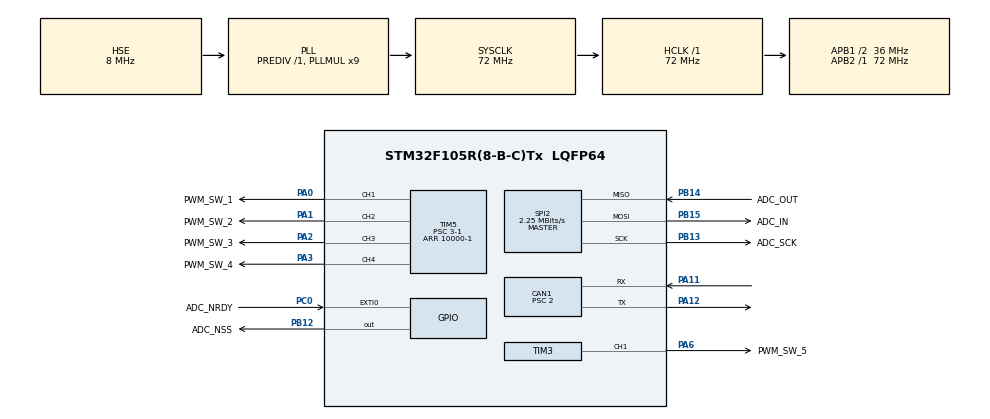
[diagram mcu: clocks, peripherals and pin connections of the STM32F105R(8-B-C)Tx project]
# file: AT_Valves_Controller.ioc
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CAN1.ABOM=ENABLE
CAN1.BS1=CAN_BS1_15TQ
CAN1.BS2=CAN_BS2_2TQ
CAN1.CalculateBaudRate=1000000
CAN1.CalculateTimeBit=1000
CAN1.CalculateTimeQuantum=55.55555555555556
CAN1.Prescaler=2
CAN1.TXFP=ENABLE
Dma.Request0=SPI2_TX
Dma.Request1=SPI2_RX
Dma.SPI2_RX.1.Direction=DMA_PERIPH_TO_MEMORY
Dma.SPI2_RX.1.Instance=DMA1_Channel4
Dma.SPI2_RX.1.MemDataAlignment=DMA_MDATAALIGN_BYTE
Dma.SPI2_RX.1.MemInc=DMA_MINC_ENABLE
Dma.SPI2_RX.1.Mode=DMA_NORMAL
Dma.SPI2_RX.1.PeriphDataAlignment=DMA_PDATAALIGN_BYTE
Dma.SPI2_RX.1.PeriphInc=DMA_PINC_DISABLE
Dma.SPI2_RX.1.Priority=DMA_PRIORITY_LOW
Dma.SPI2_TX.0.Direction=DMA_MEMORY_TO_PERIPH
Dma.SPI2_TX.0.Instance=DMA1_Channel5
Dma.SPI2_TX.0.MemDataAlignment=DMA_MDATAALIGN_BYTE
Dma.SPI2_TX.0.MemInc=DMA_MINC_ENABLE
Dma.SPI2_TX.0.Mode=DMA_NORMAL
Dma.SPI2_TX.0.PeriphDataAlignment=DMA_PDATAALIGN_BYTE
Dma.SPI2_TX.0.PeriphInc=DMA_PINC_DISABLE
Dma.SPI2_TX.0.Priority=DMA_PRIORITY_LOW
Mcu.Family=STM32F1
Mcu.Name=STM32F105R(8-B-C)Tx
Mcu.Package=LQFP64
NVIC.CAN1_RX0_IRQn=true\:0\:0\:false\:true\:true\:4\:true\:true
NVIC.CAN1_TX_IRQn=true\:0\:0\:false\:true\:true\:5\:true\:true
NVIC.DMA1_Channel4_IRQn=true\:1\:0\:true\:true\:true\:2\:true\:true
NVIC.DMA1_Channel5_IRQn=true\:1\:0\:true\:true\:true\:3\:true\:true
NVIC.EXTI0_IRQn=true\:1\:0\:true\:true\:true\:1\:true\:true
NVIC.PriorityGroup=NVIC_PRIORITYGROUP_4
NVIC.TIM6_IRQn=true\:2\:0\:true\:true\:true\:6\:true\:true
PA0-WKUP.GPIO_Label=PWM_SW_1
PA0-WKUP.GPIO_Speed=GPIO_SPEED_FREQ_HIGH
PA0-WKUP.Signal=S_TIM5_CH1
PA1.GPIO_Label=PWM_SW_2
PA1.GPIO_Speed=GPIO_SPEED_FREQ_HIGH
PA1.Signal=S_TIM5_CH2
PA11.Mode=CAN_Activate
PA11.Signal=CAN1_RX
PA12.GPIO_Speed=GPIO_SPEED_FREQ_HIGH
PA12.Mode=CAN_Activate
PA12.Signal=CAN1_TX
PA13.Mode=Serial_Wire
PA13.Signal=SYS_JTMS-SWDIO
PA14.Mode=Serial_Wire
PA14.Signal=SYS_JTCK-SWCLK
PA2.GPIO_Label=PWM_SW_3
PA2.GPIO_Speed=GPIO_SPEED_FREQ_HIGH
PA2.Signal=S_TIM5_CH3
PA3.GPIO_Label=PWM_SW_4
PA3.GPIO_Speed=GPIO_SPEED_FREQ_HIGH
PA3.Signal=S_TIM5_CH4
PA6.GPIO_Label=PWM_SW_5
PA6.GPIO_Speed=GPIO_SPEED_FREQ_HIGH
PA6.Signal=S_TIM3_CH1
PB12.GPIO_Label=ADC_NSS
PB12.GPIO_Speed=GPIO_SPEED_FREQ_HIGH
PB12.PinState=GPIO_PIN_SET
PB12.Signal=GPIO_Output
PB13.GPIO_Label=ADC_SCK
PB13.GPIO_Speed=GPIO_SPEED_FREQ_HIGH
PB13.Mode=Full_Duplex_Master
PB13.Signal=SPI2_SCK
PB14.GPIO_Label=ADC_OUT
PB14.Mode=Full_Duplex_Master
PB14.Signal=SPI2_MISO
PB15.GPIO_Label=ADC_IN
PB15.GPIO_Speed=GPIO_SPEED_FREQ_HIGH
PB15.Mode=Full_Duplex_Master
PB15.Signal=SPI2_MOSI
PC0.GPIO_Label=ADC_NRDY
PC0.GPIO_ModeDefaultEXTI=GPIO_MODE_IT_FALLING
PC0.Signal=GPXTI0
PD0-OSC_IN.Mode=HSE-External-Oscillator
PD0-OSC_IN.Signal=RCC_OSC_IN
PD1-OSC_OUT.Mode=HSE-External-Oscillator
PD1-OSC_OUT.Signal=RCC_OSC_OUT
ProjectManager.HeapSize=0x200
ProjectManager.StackSize=0x400
ProjectManager.TargetToolchain=STM32CubeIDE
RCC.AHBFreq_Value=72000000
RCC.APB1CLKDivider=RCC_HCLK_DIV2
RCC.APB1Freq_Value=36000000
RCC.APB1TimFreq_Value=72000000
RCC.APB2Freq_Value=72000000
RCC.APB2TimFreq_Value=72000000
RCC.HCLKFreq_Value=72000000
RCC.PLLMUL=RCC_PLL_MUL9
RCC.PLLSourceVirtual=RCC_PLLSOURCE_HSE
RCC.SYSCLKFreq_VALUE=72000000
RCC.SYSCLKSource=RCC_SYSCLKSOURCE_PLLCLK
RCC.USBFreq_Value=48000000
SH.S_TIM3_CH1.0=TIM3_CH1,PWM Generation1 CH1
SH.S_TIM5_CH1.0=TIM5_CH1,PWM Generation1 CH1
SH.S_TIM5_CH2.0=TIM5_CH2,PWM Generation2 CH2
SH.S_TIM5_CH3.0=TIM5_CH3,PWM Generation3 CH3
SH.S_TIM5_CH4.0=TIM5_CH4,PWM Generation4 CH4
SPI2.BaudRatePrescaler=SPI_BAUDRATEPRESCALER_16
SPI2.CLKPhase=SPI_PHASE_2EDGE
SPI2.CLKPolarity=SPI_POLARITY_HIGH
SPI2.CalculateBaudRate=2.25 MBits/s
SPI2.DataSize=SPI_DATASIZE_8BIT
SPI2.Direction=SPI_DIRECTION_2LINES
SPI2.FirstBit=SPI_FIRSTBIT_MSB
SPI2.Mode=SPI_MODE_MASTER
SPI2.VirtualType=VM_MASTER
TIM3.AutoReloadPreload=TIM_AUTORELOAD_PRELOAD_ENABLE
TIM3.Channel-PWM\ Generation1\ CH1=TIM_CHANNEL_1
TIM3.OCFastMode_PWM-PWM\ Generation1\ CH1=TIM_OCFAST_DISABLE
TIM3.OCMode_PWM-PWM\ Generation1\ CH1=TIM_OCMODE_PWM1
TIM3.OCPolarity_1=TIM_OCPOLARITY_HIGH
TIM3.Period=10000-1
TIM3.Prescaler=3-1
TIM5.AutoReloadPreload=TIM_AUTORELOAD_PRELOAD_ENABLE
TIM5.Channel-PWM\ Generation1\ CH1=TIM_CHANNEL_1
TIM5.Channel-PWM\ Generation2\ CH2=TIM_CHANNEL_2
TIM5.Channel-PWM\ Generation3\ CH3=TIM_CHANNEL_3
TIM5.Channel-PWM\ Generation4\ CH4=TIM_CHANNEL_4
TIM5.OCFastMode_PWM-PWM\ Generation1\ CH1=TIM_OCFAST_DISABLE
TIM5.OCFastMode_PWM-PWM\ Generation2\ CH2=TIM_OCFAST_DISABLE
TIM5.OCFastMode_PWM-PWM\ Generation3\ CH3=TIM_OCFAST_DISABLE
TIM5.OCFastMode_PWM-PWM\ Generation4\ CH4=TIM_OCFAST_DISABLE
TIM5.OCMode_PWM-PWM\ Generation1\ CH1=TIM_OCMODE_PWM1
TIM5.OCMode_PWM-PWM\ Generation2\ CH2=TIM_OCMODE_PWM1
TIM5.OCMode_PWM-PWM\ Generation3\ CH3=TIM_OCMODE_PWM1
TIM5.OCMode_PWM-PWM\ Generation4\ CH4=TIM_OCMODE_PWM1
TIM5.OCPolarity_1=TIM_OCPOLARITY_HIGH
TIM5.OCPolarity_2=TIM_OCPOLARITY_HIGH
TIM5.OCPolarity_3=TIM_OCPOLARITY_HIGH
TIM5.OCPolarity_4=TIM_OCPOLARITY_HIGH
TIM5.Period=10000-1
TIM5.Prescaler=3-1
TIM6.AutoReloadPreload=TIM_AUTORELOAD_PRELOAD_ENABLE
TIM6.Period=50-1
TIM6.Prescaler=7200-1
VP_TIM3_VS_ClockSourceINT.Mode=Internal
VP_TIM5_VS_ClockSourceINT.Mode=Internal
VP_TIM6_VS_ClockSourceINT.Mode=Enable_Timer
board=custom

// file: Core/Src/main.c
/* USER CODE BEGIN Header */
/**
  ******************************************************************************
  * @file           : main.c
  * @brief          : Main program body
  ******************************************************************************
  * @attention
  *
  * Copyright (c) 2023 STMicroelectronics.
  * All rights reserved.
  *
  * This software is licensed under terms that can be found in the LICENSE file
  * in the root directory of this software component.
  * If no LICENSE file comes with this software, it is provided AS-IS.
  *
  ******************************************************************************
  */
/* USER CODE END Header */
#include "main.h"
#include "can.h"
#include "dma.h"
#include "spi.h"
#include "tim.h"
#include "gpio.h"

/* USER CODE BEGIN Includes */
#include "user_logic.h"
/* USER CODE END Includes */

void SystemClock_Config(void);
static void MX_NVIC_Init(void);

int main(void)
{
  __disable_irq();

  /* MCU Configuration--------------------------------------------------------*/

  /* Reset of all peripherals, Initializes the Flash interface and the Systick. */
  HAL_Init();

  /* Configure the system clock */
  SystemClock_Config();

  /* Initialize all configured peripherals */
  MX_GPIO_Init();
  MX_DMA_Init();
  MX_CAN1_Init();
  MX_SPI2_Init();
  MX_TIM3_Init();
  MX_TIM5_Init();
  MX_TIM6_Init();

  /* Initialize interrupts */
  MX_NVIC_Init();
  /* USER CODE BEGIN 2 */
  User_Init();
  __enable_irq();
  /* USER CODE END 2 */

  /* Infinite loop */
  while (1)
  {

    /* USER CODE BEGIN 3 */
    User_update();
  }
  /* USER CODE END 3 */
}

void SystemClock_Config(void)
{
  RCC_OscInitTypeDef RCC_OscInitStruct = {0};
  RCC_ClkInitTypeDef RCC_ClkInitStruct = {0};

  /** Initializes the RCC Oscillators according to the specified parameters
  * in the RCC_OscInitTypeDef structure.
  */
  RCC_OscInitStruct.OscillatorType = RCC_OSCILLATORTYPE_HSE;
  RCC_OscInitStruct.HSEState = RCC_HSE_ON;
  RCC_OscInitStruct.HSEPredivValue = RCC_HSE_PREDIV_DIV1;
  RCC_OscInitStruct.HSIState = RCC_HSI_ON;
  RCC_OscInitStruct.Prediv1Source = RCC_PREDIV1_SOURCE_HSE;
  RCC_OscInitStruct.PLL.PLLState = RCC_PLL_ON;
  RCC_OscInitStruct.PLL.PLLSource = RCC_PLLSOURCE_HSE;
  RCC_OscInitStruct.PLL.PLLMUL = RCC_PLL_MUL9;
  RCC_OscInitStruct.PLL2.PLL2State = RCC_PLL_NONE;
  if (HAL_RCC_OscConfig(&RCC_OscInitStruct) != HAL_OK)
  {
    Error_Handler();
  }
  /** Initializes the CPU, AHB and APB buses clocks
  */
  RCC_ClkInitStruct.ClockType = RCC_CLOCKTYPE_HCLK|RCC_CLOCKTYPE_SYSCLK
                              |RCC_CLOCKTYPE_PCLK1|RCC_CLOCKTYPE_PCLK2;
  RCC_ClkInitStruct.SYSCLKSource = RCC_SYSCLKSOURCE_PLLCLK;
  RCC_ClkInitStruct.AHBCLKDivider = RCC_SYSCLK_DIV1;
  RCC_ClkInitStruct.APB1CLKDivider = RCC_HCLK_DIV2;
  RCC_ClkInitStruct.APB2CLKDivider = RCC_HCLK_DIV1;

  if (HAL_RCC_ClockConfig(&RCC_ClkInitStruct, FLASH_LATENCY_2) != HAL_OK)
  {
    Error_Handler();
  }
  /** Configure the Systick interrupt time
  */
  __HAL_RCC_PLLI2S_ENABLE();
}

/**
  * @brief NVIC Configuration.
  * @retval None
  */
static void MX_NVIC_Init(void)
{
  /* EXTI0_IRQn interrupt configuration */
  HAL_NVIC_SetPriority(EXTI0_IRQn, 1, 0);
  HAL_NVIC_EnableIRQ(EXTI0_IRQn);
  /* DMA1_Channel4_IRQn interrupt configuration */
  HAL_NVIC_SetPriority(DMA1_Channel4_IRQn, 1, 0);
  HAL_NVIC_EnableIRQ(DMA1_Channel4_IRQn);
  /* DMA1_Channel5_IRQn interrupt configuration */
  HAL_NVIC_SetPriority(DMA1_Channel5_IRQn, 1, 0);
  HAL_NVIC_EnableIRQ(DMA1_Channel5_IRQn);
  /* CAN1_RX0_IRQn interrupt configuration */
  HAL_NVIC_SetPriority(CAN1_RX0_IRQn, 0, 0);
  HAL_NVIC_EnableIRQ(CAN1_RX0_IRQn);
  /* CAN1_TX_IRQn interrupt configuration */
  HAL_NVIC_SetPriority(CAN1_TX_IRQn, 0, 0);
  HAL_NVIC_EnableIRQ(CAN1_TX_IRQn);
  /* TIM6_IRQn interrupt configuration */
  HAL_NVIC_SetPriority(TIM6_IRQn, 2, 0);
  HAL_NVIC_EnableIRQ(TIM6_IRQn);
}

void Error_Handler(void)
{
  __disable_irq();
  while (1)
  {
  }
}
